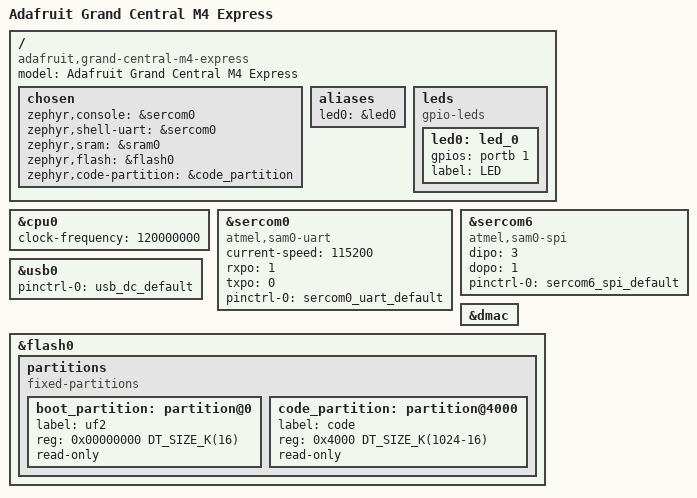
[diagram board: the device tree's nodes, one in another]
/*
 * Copyright (c) 2023 Lukas Jung <lukas.jung@mailbox.org>
 * SPDX-License-Identifier: Apache-2.0
 */

/dts-v1/;
#include <atmel/samd5xx20.dtsi>
#include "adafruit_grand_central_m4_express-pinctrl.dtsi"

/ {
	model = "Adafruit Grand Central M4 Express";
	compatible = "adafruit,grand-central-m4-express";

	chosen {
		zephyr,console = &sercom0;
		zephyr,shell-uart = &sercom0;
		zephyr,sram = &sram0;
		zephyr,flash = &flash0;
		zephyr,code-partition = &code_partition;
	};

	/* These aliases are provided for compatibility with samples */
	aliases {
		led0 = &led0;
	};

	leds {
		compatible = "gpio-leds";
		led0: led_0 {
			gpios = <&portb 1 0>;
			label = "LED";
		};
	};
};

&cpu0 {
	clock-frequency = <120000000>;
};

&sercom0 {
	status = "okay";
	compatible = "atmel,sam0-uart";
	current-speed = <115200>;
	rxpo = <1>;
	txpo = <0>;

	pinctrl-0 = <&sercom0_uart_default>;
	pinctrl-names = "default";
};

&sercom6 {
	status = "okay";
	compatible = "atmel,sam0-spi";
	dipo = <3>;
	dopo = <1>;

	#address-cells = <1>;
	#size-cells = <0>;

	pinctrl-0 = <&sercom6_spi_default>;
	pinctrl-names = "default";
};

zephyr_udc0: &usb0 {
	status = "okay";

	pinctrl-0 = <&usb_dc_default>;
	pinctrl-names = "default";
};

&dmac {
	status = "okay";
};

&flash0 {
	partitions {
		compatible = "fixed-partitions";
		#address-cells = <1>;
		#size-cells = <1>;

		boot_partition: partition@0 {
			label = "uf2";
			reg = <0x00000000 DT_SIZE_K(16)>;
			read-only;
		};

		code_partition: partition@4000 {
			label = "code";
			reg = <0x4000 DT_SIZE_K(1024-16)>;
			read-only;
		};
	};
};
